# ATmega324PA device description
Architecture: AVR8; Family: megaAVR
Registers are 8-bit, access not given, no defined reset value unless marked. A register's access mark holds for its fields unless they carry their own. Offsets are from the block's base; [hi:lo] are bit positions; {n}, {i} and the like mark numbered series.

## WDT — Watchdog Timer
Instances: WDT 0x00
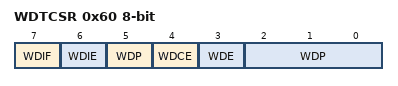
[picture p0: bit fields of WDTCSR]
0x60 WDTCSR — Watchdog Timer Control Register
  [7] WDIF — Watchdog Timeout Interrupt Flag
  [6] WDIE — Watchdog Timeout Interrupt Enable
  [4] WDCE — Watchdog Change Enable
  [3] WDE — Watch Dog Enable
  [5,2:0] WDP — Watchdog Timer Prescaler Bits
    0=Oscillator Cycles 2K; 1=Oscillator Cycles 4K; 2=Oscillator Cycles 8K; 3=Oscillator Cycles 16K; 4=Oscillator Cycles 32K; 5=Oscillator Cycles 64K; 6=Oscillator Cycles 128K; 7=Oscillator Cycles 256K; 8=Oscillator Cycles 512K; 9=Oscillator Cycles 1024K

## JTAG — JTAG Interface
Instances: JTAG 0x00
0x51 OCDR — On-Chip Debug Related Register in I/O Memory
0x54 MCUSR — MCU Status Register
  [4] JTRF — JTAG Reset Flag
0x55 MCUCR — MCU Control Register
  [7] JTD — JTAG Interface Disable

## BOOT_LOAD — Bootloader
Instances: BOOT_LOAD 0x00
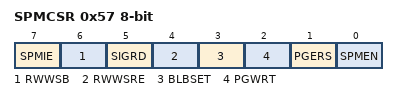
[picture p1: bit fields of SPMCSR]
0x57 SPMCSR — Store Program Memory Control Register
  [7] SPMIE — SPM Interrupt Enable
  [6] RWWSB — Read While Write Section Busy
  [5] SIGRD — Signature Row Read
  [4] RWWSRE — Read While Write section read enable
  [3] BLBSET — Boot Lock Bit Set
  [2] PGWRT — Page Write
  [1] PGERS — Page Erase
  [0] SPMEN — Store Program Memory Enable

## EXINT — External Interrupts
Instances: EXINT 0x00
0x3B PCIFR — Pin Change Interrupt Flag Register
  [3:0] PCIF — Pin Change Interrupt Flags
0x3C EIFR — External Interrupt Flag Register
  [2:0] INTF — External Interrupt Flags
0x3D EIMSK — External Interrupt Mask Register
  [2:0] INT — External Interrupt Request 2 Enable
0x68 PCICR — Pin Change Interrupt Control Register
  [3:0] PCIE — Pin Change Interrupt Enables
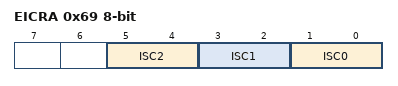
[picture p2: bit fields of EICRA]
0x69 EICRA — External Interrupt Control Register A
  [all] fields
    0=Low Level of INTX; 1=Any Logical Change of INTX; 2=Falling Edge of INTX; 3=Rising Edge of INTX
  [5:4] ISC2 — External Interrupt Sense Control Bit
  [3:2] ISC1 — External Interrupt Sense Control Bit
  [1:0] ISC0 — External Interrupt Sense Control Bit
0x6B PCMSK0 — Pin Change Mask Register 0
  [7:0] PCINT — Pin Change Enable Masks
0x6C PCMSK1 — Pin Change Mask Register 1
  [7:0] PCINT (bit 8 of the value upward) — Pin Change Enable Masks
0x6D PCMSK2 — Pin Change Mask Register 2
  [7:0] PCINT (bit 16 of the value upward) — Pin Change Enable Masks
0x73 PCMSK3 — Pin Change Mask Register 3
  [7:0] PCINT (bit 24 of the value upward) — Pin Change Enable Masks

## ADC — Analog-to-Digital Converter
Instances: ADC 0x00
0x78 ADC 16-bit — ADC Data Register Bytes
  [9:0] ADC — ADC Data bits
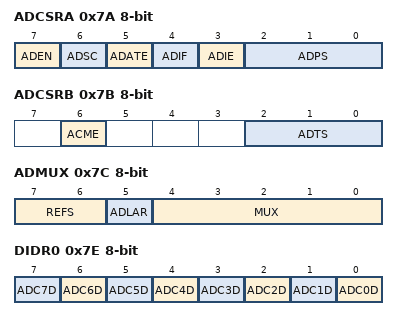
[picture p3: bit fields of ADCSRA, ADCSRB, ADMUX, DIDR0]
0x7A ADCSRA — The ADC Control and Status register A
  [7] ADEN — ADC Enable
  [6] ADSC — ADC Start Conversion
  [5] ADATE — ADC Auto Trigger Enable
  [4] ADIF — ADC Interrupt Flag
  [3] ADIE — ADC Interrupt Enable
  [2:0] ADPS — ADC Prescaler Select Bits
    0=2; 1=2; 2=4; 3=8; 4=16; 5=32; 6=64; 7=128
0x7B ADCSRB — The ADC Control and Status register B
  [6] ACME
  [2:0] ADTS — ADC Auto Trigger Source bits
    0=Free Running mode; 1=Analog Comparator; 2=External Interrupt Request 0; 3=Timer/Counter0 Compare Match A; 4=Timer/Counter0 Overflow; 5=Timer/Counter1 Compare Match B; 6=Timer/Counter1 Overflow; 7=Timer/Counter1 Capture Event
0x7C ADMUX — The ADC multiplexer Selection Register
  [7:6] REFS — Reference Selection Bits
    0=AREF, Internal Vref turned off; 1=AVCC with external capacitor at AREF pin; 2=Internal 1.1V Voltage Reference with external capacitor at AREF pin; 3=Internal 2.56V Voltage Reference with external capacitor at AREF pin
  [5] ADLAR — Left Adjust Result
  [4:0] MUX — Analog Channel and Gain Selection Bits
    {v}=ADC{v} (ADC Single Ended Input pin {v}) (v=0..7); 8=ADC0_ADC0_10X (ADC Differential Inputs Postive pin 0 Negative pin 0 10x Gain); 9=ADC1_ADC0_10X (ADC Differential Inputs Postive pin 1 Negative pin 0 10x Gain); 10=ADC0_ADC0_200x (ADC Differential Inputs Postive pin 0 Negative pin 0 200x Gain); 11=ADC1_ADC0_200X (ADC Differential Inputs Postive pin 1 Negative pin 0 200x Gain); 12=ADC2_ADC2_10X (ADC Differential Inputs Postive pin 2 Negative pin 2 10x Gain); 13=ADC3_ADC2_10X (ADC Differential Inputs Postive pin 3 Negative pin 2 10x Gain); 14=ADC2_ADC2_200X (ADC Differential Inputs Postive pin 2 Negative pin 2 200x Gain); 15=ADC3_ADC2_200X (ADC Differential Inputs Postive pin 3 Negative pin 2 200x Gain); {v}=ADC{v-16}_ADC1_1X (ADC Differential Inputs Postive pin {v-16} Negative pin 1 1x Gain) (v=16..23); {v}=ADC{v-24}_ADC2_1X (ADC Differential Inputs Postive pin {v-24} Negative pin 2 1x Gain) (v=24..29); 30=ADC_VBG (Internal Reference (VBG)); 31=ADC_GND (0V (GND))
0x7E DIDR0 — Digital Input Disable Register
  [n] ADC{n}D (n=0..7)
